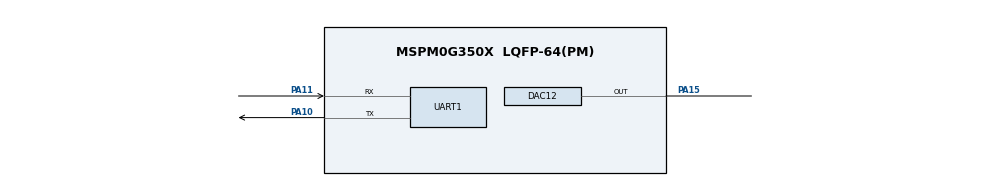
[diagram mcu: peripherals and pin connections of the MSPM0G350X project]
/**
 * @cliArgs --device "MSPM0G350X" --part "Default" --package "LQFP-64(PM)" --product "mspm0_sdk@2.10.00.04"
 * @versions {"tool":"1.26.2+4477"}
 */

/**
 * Import the modules used in this configuration.
 */
const ADC12  = scripting.addModule("/ti/driverlib/ADC12", {}, false);
const ADC121 = ADC12.addInstance();
const DAC12  = scripting.addModule("/ti/driverlib/DAC12");
const DMA    = scripting.addModule("/ti/driverlib/DMA");
const SYSCTL = scripting.addModule("/ti/driverlib/SYSCTL");
const TIMER  = scripting.addModule("/ti/driverlib/TIMER", {}, false);
const TIMER1 = TIMER.addInstance();
const UART   = scripting.addModule("/ti/driverlib/UART", {}, false);
const UART1  = UART.addInstance();

/**
 * Write custom configuration values to the imported modules.
 */
const gate7  = system.clockTree["MFCLKGATE"];
gate7.enable = true;

const gate8  = system.clockTree["MFPCLKGATE"];
gate8.enable = true;

ADC121.$name                      = "ADC12_0";
ADC121.peripheral.adcPin0.$assign = "PA27";
ADC121.adcPin0Config.$name        = "ti_driverlib_gpio_GPIOPinGeneric3";
ADC121.adcPin0Config.enableConfig = true;

const Board = scripting.addModule("/ti/driverlib/Board", {}, false);

DAC12.dacOutputPinEn            = true;
DAC12.dacAmplifier              = "ON";
DAC12.peripheral.$assign        = "DAC0";
DAC12.peripheral.OutPin.$assign = "PA15";
DAC12.OutPinConfig.$name        = "ti_driverlib_gpio_GPIOPinGeneric0";

DMA.associatedChannels.create(1);
DMA.associatedChannels[0].$name = "DMA_CH0";

SYSCTL.forceDefaultClkConfig = true;
SYSCTL.clockTreeEn           = true;
SYSCTL.MFPCLKEn              = true;
SYSCTL.HFCLK4MFPCLKDIV       = "8";

TIMER1.$name      = "TIMG_0";
TIMER1.timerMode  = "PERIODIC_UP";
TIMER1.interrupts = ["ZERO"];

UART1.$name                    = "UART_0";
UART1.targetBaudRate           = 2000000;
UART1.enabledInterrupts        = ["RX"];
UART1.peripheral.$assign       = "UART0";
UART1.peripheral.rxPin.$assign = "PA11";
UART1.peripheral.txPin.$assign = "PA10";
UART1.txPinConfig.$name        = "ti_driverlib_gpio_GPIOPinGeneric1";
UART1.txPinConfig.enableConfig = true;
UART1.rxPinConfig.$name        = "ti_driverlib_gpio_GPIOPinGeneric2";

/**
 * Pinmux solution for unlocked pins/peripherals. This ensures that minor changes to the automatic solver in a future
 * version of the tool will not impact the pinmux you originally saw.  These lines can be completely deleted in order to
 * re-solve from scratch.
 */
ADC121.peripheral.$suggestSolution                    = "ADC0";
Board.peripheral.$suggestSolution                     = "DEBUGSS";
Board.peripheral.swclkPin.$suggestSolution            = "PA20";
Board.peripheral.swdioPin.$suggestSolution            = "PA19";
DMA.associatedChannels[0].peripheral.$suggestSolution = "DMA_CH0";
TIMER1.peripheral.$suggestSolution                    = "TIMA0";
